# ISD9300_v3 register map
File version: 1.0
Registers are 32-bit, read-write, reset 0x0 unless marked. A register's access mark holds for its fields unless they carry their own. Offsets are from the block's base; [hi:lo] are bit positions; 'fields as' and 'values as' point back to an identical list.

## CLK — CLK Register Map
Base 0x50000200
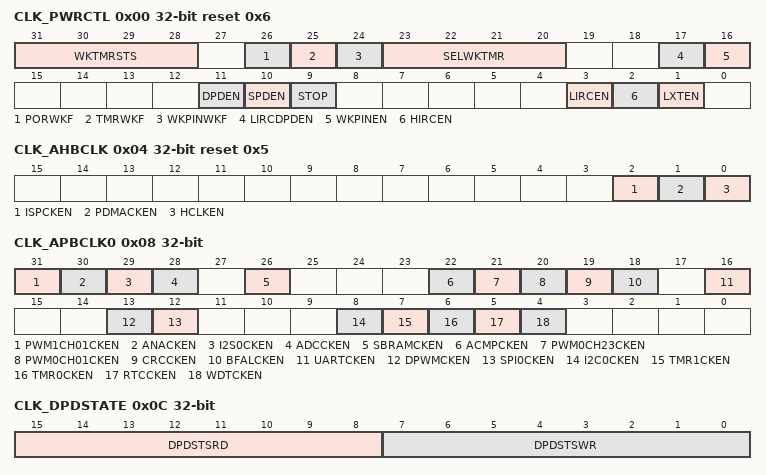
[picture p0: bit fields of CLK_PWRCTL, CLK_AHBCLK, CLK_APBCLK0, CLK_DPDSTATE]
0x00 CLK_PWRCTL reset 0x6 (reset mask 0xFFFFFF) — System Power Control Register
  [31:28] WKTMRSTS — Current Wakeup Timer Setting. Read-Only. Read back of the current WAKEUP timer setting. This value is updated with SELWKTMR upon entering DPD mode.
  [26] PORWKF — POR Wakeup Flag. Read Only. This flag indicates that wakeup of device was requested with a power-on reset. Flag is cleared when DPD mode is entered.
  [25] TMRWKF — Timer Wakeup Flag. Read Only. This flag indicates that wakeup of device was requested with TIMER count of the 16Khz oscillator. Flag is cleared when DPD mode is entered.
  [24] WKPINWKF — Pin Wakeup Flag. Read Only. This flag indicates that wakeup of device was requested with a high to low transition of the WAKEUP pin. Flag is cleared when DPD mode is entered.
  [23:20] SELWKTMR — Select Wakeup Timer. SELWKTMR[0] aaa 1: WAKEUP after 128 OSC16K clocks (12.8 ms). SELWKTMR[1] aaa 1: WAKEUP after 256 OSC16K clocks (25.6 ms). SELWKTMR[2] aaa 1: WAKEUP after 512 OSC16K clocks (51.2 ms). SELWKTMR[3] aaa 1: WAKEUP after 1024 OSC16K clocks (102.4ms)
  [17] LIRCDPDEN — OSC16K Enabled Control. Determines whether OSC16K is enabled in DPD mode. If OSC16K is disabled, device cannot wake from DPD with SELWKTMR delay.
    0=enabled; 1=disabled
  [16] WKPINEN — Wakeup Pin Enabled Control. Determines whether WAKEUP pin is enabled in DPD mode.
    0=enabled; 1=disabled
  [11] DPDEN — Deep Power Down (DPD) Bit. Set to '1' and issue WFI/WFE instruction to enter DPD mode.
  [10] SPDEN — Standby Power Down (SPD) Bit. Set to '1' and issue WFI/WFE instruction to enter SPD mode.
  [9] STOP — Stop. RESERVED - do not set to '1'
  [3] LIRCEN — OSC16K Oscillator Enable Bit
    0=disable; 1=enable (default)
  [2] HIRCEN — OSC49M Oscillator Enable Bit
    0=disable; 1=enable (default)
  [1] LXTEN — External 32.768 KHz Crystal Enable Bit
    0=disable (default); 1=enable
0x04 CLK_AHBCLK reset 0x5 — AHB Device Clock Enable Control Register
  [2] ISPCKEN — Flash ISP Controller Clock Enable Control
    0=To disable the Flash ISP engine clock; 1=To enable the Flash ISP engine clock
  [1] PDMACKEN — PDMA Controller Clock Enable Control
    0=To disable the PDMA engine clock; 1=To enable the PDMA engine clock
  [0] HCLKEN — CPU Clock Enable (HCLK). Must be left as '1' for normal operation.
0x08 CLK_APBCLK0 — APB Device Clock Enable Control Register
  [all] fields
    0=Disable; 1=Enable
  [31] PWM1CH01CKEN — PWM1CH0 And PWM1CH1 Clock Enable Control
  [30] ANACKEN — Analog Block Clock Enable Control
  [29] I2S0CKEN — I2S Clock Enable Control
  [28] ADCCKEN — Audio Analog-Digital-Converter (ADC) Clock Enable Control
  [26] SBRAMCKEN — Standby RAM Clock Enable Control
  [22] ACMPCKEN — Analog Comparator Clock Enable Control
  [21] PWM0CH23CKEN — PWM0CH2 And PWM0CH3 Block Clock Enable Control
  [20] PWM0CH01CKEN — PWM0CH0 And PWM0CH1 Block Clock Enable Control
  [19] CRCCKEN — Cyclic Redundancy Check Block Clock Enable Control
  [18] BFALCKEN — Biquad Filter And Automatic Level Control Block Clock Enable Control
  [16] UARTCKEN — UART Clock Enable Control
  [13] DPWMCKEN — Differential PWM Speaker Driver Clock Enable Control
  [12] SPI0CKEN — SPI0 Clock Enable Control
  [8] I2C0CKEN — I2C0 Clock Enable Control
  [7] TMR1CKEN — Timer1 Clock Enable Control
  [6] TMR0CKEN — Timer0 Clock Enable Control
  [5] RTCCKEN — Real-Time-Clock APB Interface Clock Control
  [4] WDTCKEN — Watchdog Clock Enable Control
0x0C CLK_DPDSTATE (reset mask 0xFFFF00FF) — Deep Power Down State Register
  [15:8] DPDSTSRD — DPD State Read Back. Read back of CLK_DPDSTATE register. This register was preserved from last DPD event .
  [7:0] DPDSTSWR — DPD State Write. To set the CLK_DPDSTATE register, write value to this register. Data is latched on next DPD event.
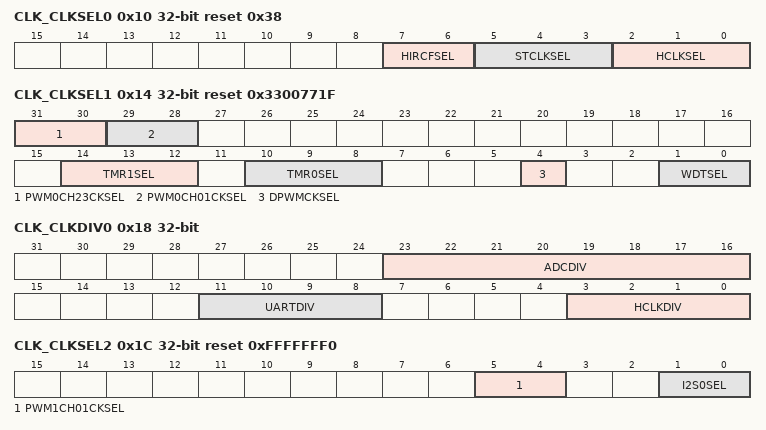
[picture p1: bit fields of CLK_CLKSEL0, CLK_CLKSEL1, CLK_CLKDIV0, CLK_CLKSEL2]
0x10 CLK_CLKSEL0 reset 0x38 — Clock Source Select Control Register 0
  [7:6] HIRCFSEL — OSC48M Frequency Select. Determines which trim setting to use for OSC48M internal oscillator. Oscillator is factory trimmed within 1% to: 0: 49.152MHz (Default). 1: 32.768MHz. 2: 36.864MHz
  [5:3] STCLKSEL — MCU Cortex_M0 SYST Clock Source Select. These bits are protected, to write to bits first perform the unlock sequence (see Protected Register Lock Key Register (SYS_REGLCTL)). 000 aaa clock source from 16kHz internal clock. 001 aaa clock source from external 32kHz crystal clock. 010 aaa clock source from 16kHz internal oscillator divided by 2. 011 aaa clock source from OSC49M internal oscillator divided by 2. 1xx aaa clock source from HCLK÷2 (Default). Note that to use STCLKSEL as source of SysTic timer the CLKSRC bit of SYST_CSR must be set to 0.
  [2:0] HCLKSEL — HCLK Clock Source Select. Ensure that related clock sources (pre-select and new-select) are enabled before updating register. These bits are protected, to write to bits first perform the unlock sequence (see Protected Register Lock Key Register (SYS_REGLCTL)). 000 aaa clock source from internal OSC48M oscillator. 001 aaa clock source from external 32kHz crystal clock. 010 aaa clock source from internal 16kHz oscillator clock. 100 aaa CLK2X a frequency doubled output of OSC48M, only available on M and H speed grade devices. Others aaa RESERVED
0x14 CLK_CLKSEL1 reset 0x3300771F — Clock Source Select Control Register 1
  [31:30] PWM0CH23CKSEL — PWM0CH2 And PWM0CH3 Clock Source Select. PWM0CH2 and PWM0CH3 uses the same clock source, and pre-scaler
    0=clock source from internal 16kHz oscillator; 1=clock source from external 32kHz crystal clock; 2=clock source from HCLK; 3=clock source from internal OSC48M oscillator clock
  [29:28] PWM0CH01CKSEL — PWM0CH0 And PWM0CH1 Clock Source Select. PWM0CH0 and PWM0CH1 uses the same clock source, and pre-scaler
    values as PWM0CH23CKSEL
  [14:12] TMR1SEL — TIMER1 Clock Source Select. 000 aaa clock source from internal 16kHz oscillator. 001 aaa clock source from external 32kHz crystal clock. 010 aaa clock source from HCLK. 011 aaa clock source from external pin (GPIOA[15]). 1xx aaa clock source from internal OSC48M oscillator clock
  [10:8] TMR0SEL — TIMER0 Clock Source Select. 000 aaa clock source from internal 16kHz oscillator. 001 aaa clock source from external 32kHz crystal clock. 010 aaa clock source from HCLK. 011 aaa clock source from external pin (GPIOA[14]). 1xx aaa clock source from internal OSC48M oscillator clock
  [4] DPWMCKSEL — Differential Speaker Driver PWM Clock Source Select
    0=OSC48M clock; 1=2x OSC48M clock
  [1:0] WDTSEL — WDT Clock Source Select
    0=clock source from internal OSC48M oscillator clock; 1=clock source from external 32kHz crystal clock; 2=clock source from HCLK/2048 clock; 3=clock source from internal 16kHz oscillator clock
0x18 CLK_CLKDIV0 — Clock Divider Number Register
  [23:16] ADCDIV — ADC Clock Divide Number From ADC Clock Source. The ADC clock frequency aaa (ADC clock source frequency ) / (ADC_N + 1)
  [11:8] UARTDIV — UART Clock Divide Number From UART Clock Source. The UART clock frequency aaa (UART clock source frequency ) / (UART_N + 1)
  [3:0] HCLKDIV — HCLK Clock Divide Number From HCLK Clock Source. The HCLK clock frequency aaa (HCLK clock source frequency) / (HCLK_N + 1)
0x1C CLK_CLKSEL2 reset 0xFFFFFFF0 (reset mask 0xFFFFFFF0) — Clock Source Select Control Register 2
  [5:4] PWM1CH01CKSEL — PWM1CH0 And PWM1CH1 Clock Source Select. PWM1CH0 and PWM1CH1 uses the same clock source, and pre-scaler
    values as CLK_CLKSEL1.PWM0CH23CKSEL
  [1:0] I2S0SEL — I2S0 Clock Source Select
    values as CLK_CLKSEL1.PWM0CH23CKSEL
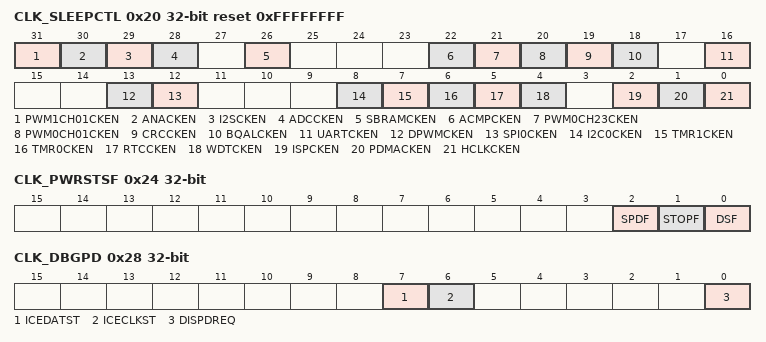
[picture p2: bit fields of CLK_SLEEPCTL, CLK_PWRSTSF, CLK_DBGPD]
0x20 CLK_SLEEPCTL reset 0xFFFFFFFF — Sleep Clock Source Select Register
  [all] fields
    0=Disable; 1=Enable
  [31] PWM1CH01CKEN — PWM1CH0 And PWM1CH1 Block Sleep Clock Enable Control
  [30] ANACKEN — Analog Block Sleep Clock Enable Control
  [29] I2SCKEN — I2S Sleep Clock Enable Control
  [28] ADCCKEN — Audio Analog-Digital-Converter (ADC) Sleep Clock Enable Control
  [26] SBRAMCKEN — Standby RAM Sleep Clock Enable Control
  [22] ACMPCKEN — Analog Comparator Sleep Clock Enable Control
  [21] PWM0CH23CKEN — PWM0CH2 And PWM0CH3 Block Sleep Clock Enable Control
  [20] PWM0CH01CKEN — PWM0CH0 And PWM0CH1 Block Sleep Clock Enable Control
  [19] CRCCKEN — Cyclic Redundancy Check Sleep Block Clock Enable Control
  [18] BQALCKEN — Biquad Filter/ALC Block Sleep Clock Enable Control
  [16] UARTCKEN — UART Sleep Clock Enable Control
  [13] DPWMCKEN — Differential PWM Speaker Driver Sleep Clock Enable Control
  [12] SPI0CKEN — SPI0 Sleep Clock Enable Control
  [8] I2C0CKEN — I2C0 Sleep Clock Enable Control
  [7] TMR1CKEN — Timer1 Sleep Clock Enable Control
  [6] TMR0CKEN — Timer0 Sleep Clock Enable Control
  [5] RTCCKEN — Real-Time- Sleep Clock APB Interface Clock Control
  [4] WDTCKEN — Watchdog Sleep Clock Enable Control
  [2] ISPCKEN — Flash ISP Controller Sleep Clock Enable Control
  [1] PDMACKEN — PDMA Controller Sleep Clock Enable Control
  [0] HCLKCKEN — CPU Clock Sleep Enable (HCLK). Must be left as '1' for normal operation.
0x24 CLK_PWRSTSF — Power State Flag Register
  [2] SPDF — Powered Down Flag. This flag is set if core logic was powered down to Standby (SPD). Write '1' to clear flag.
  [1] STOPF — Stop Flag. This flag is set if core logic was stopped but not powered down. Write '1' to clear flag.
  [0] DSF — Deep Sleep Flag. This flag is set if core logic was placed in Deep Sleep mode. Write '1' to clear flag.
0x28 CLK_DBGPD (reset mask 0xFFFFFF00) — Debug Port Power Down Disable Register
  [7] ICEDATST — ICEDATST Pin State. Read Only. Current state of ICE_DAT pin.
  [6] ICECLKST — ICECLKST Pin State. Read Only. Current state of ICE_CLK pin.
  [0] DISPDREQ — Disable Power Down
    0=Enable power down requests; 1=Disable power down requests
